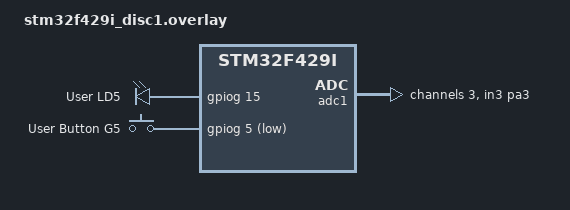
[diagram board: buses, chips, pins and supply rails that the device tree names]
/ {
	leds {
		compatible = "gpio-leds";

		external_led_5: led_5 {
			gpios = <&gpiog 15 GPIO_ACTIVE_HIGH>;
			label = "User LD5";
		};
	};

	buttons {
		compatible = "gpio-keys";
		polling-mode;

		button_1: button {
			gpios = <&gpiog 5 GPIO_ACTIVE_LOW>;
			label = "User Button G5";
		};
	};

	aliases {
		led2 = &external_led_5;
		my-button = &button_1;
		my-adc = &adc1;
		my-adc-channel = &adc1_ch3;
	};
};

&pinctrl {
	adc1_in3_pa3: adc1_in3_pa3 {
		pinmux = <STM32_PINMUX('A', 3, ANALOG)>;
	};
};

&adc1 {
	status = "okay";
	pinctrl-0 = <&adc1_in3_pa3>;
	pinctrl-names = "default";
	st,adc-prescaler = <2>;

	#address-cells = <1>;
	#size-cells = <0>;

	adc1_ch3: channel@3 {
		reg = <3>;
		zephyr,gain = "ADC_GAIN_1";
		zephyr,reference = "ADC_REF_INTERNAL";
		zephyr,acquisition-time = <ADC_ACQ_TIME_DEFAULT>;
		zephyr,resolution = <12>;
		zephyr,vref-mv = <3300>;
	};
};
